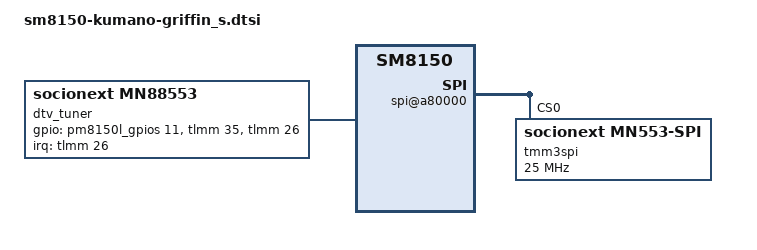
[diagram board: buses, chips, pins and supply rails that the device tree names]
/* arch/arm64/boot/dts/somc/sm8150-kumano-griffin_s.dtsi
 *
 * This program is free software; you can redistribute it and/or modify
 * it under the terms of the GNU General Public License version 2 and
 * only version 2 as published by the Free Software Foundation.
 *
 * This program is distributed in the hope that it will be useful,
 * but WITHOUT ANY WARRANTY; without even the implied warranty of
 * MERCHANTABILITY or FITNESS FOR A PARTICULAR PURPOSE.  See the
 * GNU General Public License for more details.
 */

#include "sm8150-kumano-griffin_jp-common.dtsi"

&soc {
	/* SPI: QUP8 */
	spi@a80000 {
		status = "okay";
		tmm3spi@0 {
			compatible = "socionext,mn553-spi";
			reg = <0>;
			spi-max-frequency = <25000000>;
			spi-mode = <0>;
		};
	};

	dtv_tuner: mn88553 {
		compatible = "socionext,mn88553";
		interrupt-parent = <&tlmm>;
		interrupts = <26 0>;
		gpios = <&pm8150l_gpios 11 0>,         /* DTV_PWR_EN */
				<&tlmm 35 0>,          /* DTV_RST_N  */
				<&tlmm 26 0>;          /* DTV_INT    */
	};
};

&android_q_fstab {
	carrier {
		compatible = "android,vendor";
		dev = "/dev/block/platform/soc/1d84000.ufshc/by-name/carrier";
		type = "ext4";
		mnt_flags = "rw,barrier=1,noatime";
		fsmgr_flags = "wait,nofail";
		status = "ok";
	};
};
